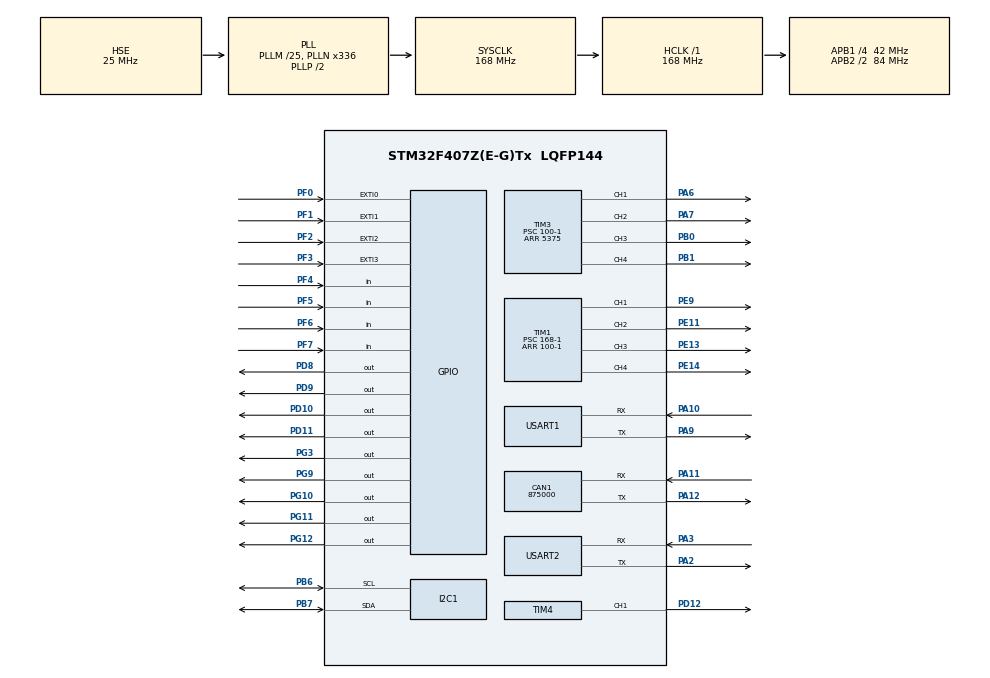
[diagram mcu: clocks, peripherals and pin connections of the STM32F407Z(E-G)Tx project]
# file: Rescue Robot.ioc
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CAN1.BS1=CAN_BS1_1TQ
CAN1.BS2=CAN_BS2_1TQ
CAN1.CalculateBaudRate=875000
CAN1.CalculateTimeBit=1142
CAN1.CalculateTimeQuantum=380.95238095238096
Mcu.Family=STM32F4
Mcu.Name=STM32F407Z(E-G)Tx
Mcu.Package=LQFP144
NVIC.PriorityGroup=NVIC_PRIORITYGROUP_4
PA10.Mode=Asynchronous
PA10.Signal=USART1_RX
PA11.Mode=CAN_Activate
PA11.Signal=CAN1_RX
PA12.Mode=CAN_Activate
PA12.Signal=CAN1_TX
PA13.Mode=Serial_Wire
PA13.Signal=SYS_JTMS-SWDIO
PA14.Mode=Serial_Wire
PA14.Signal=SYS_JTCK-SWCLK
PA2.Mode=Asynchronous
PA2.Signal=USART2_TX
PA3.Mode=Asynchronous
PA3.Signal=USART2_RX
PA6.Signal=S_TIM3_CH1
PA7.Signal=S_TIM3_CH2
PA9.Mode=Asynchronous
PA9.Signal=USART1_TX
PB0.Signal=S_TIM3_CH3
PB1.Signal=S_TIM3_CH4
PB6.Mode=I2C
PB6.Signal=I2C1_SCL
PB7.Mode=I2C
PB7.Signal=I2C1_SDA
PD10.GPIO_Speed=GPIO_SPEED_FREQ_VERY_HIGH
PD10.Signal=GPIO_Output
PD11.GPIO_Speed=GPIO_SPEED_FREQ_VERY_HIGH
PD11.Signal=GPIO_Output
PD12.Signal=S_TIM4_CH1
PD8.GPIO_Speed=GPIO_SPEED_FREQ_VERY_HIGH
PD8.Signal=GPIO_Output
PD9.GPIO_Speed=GPIO_SPEED_FREQ_VERY_HIGH
PD9.Signal=GPIO_Output
PE11.Signal=S_TIM1_CH2
PE13.Signal=S_TIM1_CH3
PE14.Signal=S_TIM1_CH4
PE9.Signal=S_TIM1_CH1
PF0.GPIO_ModeDefaultEXTI=GPIO_MODE_IT_RISING_FALLING
PF0.Signal=GPXTI0
PF1.GPIO_ModeDefaultEXTI=GPIO_MODE_IT_RISING_FALLING
PF1.Signal=GPXTI1
PF2.GPIO_ModeDefaultEXTI=GPIO_MODE_IT_RISING_FALLING
PF2.Signal=GPXTI2
PF3.GPIO_ModeDefaultEXTI=GPIO_MODE_IT_RISING_FALLING
PF3.Signal=GPXTI3
PF4.GPIO_Mode=GPIO_MODE_INPUT
PF4.Signal=GPIO_Input
PF5.GPIO_Mode=GPIO_MODE_INPUT
PF5.Signal=GPIO_Input
PF6.GPIO_Mode=GPIO_MODE_INPUT
PF6.Signal=GPIO_Input
PF7.GPIO_Mode=GPIO_MODE_INPUT
PF7.Signal=GPIO_Input
PG10.GPIO_Speed=GPIO_SPEED_FREQ_VERY_HIGH
PG10.Signal=GPIO_Output
PG11.GPIO_Speed=GPIO_SPEED_FREQ_VERY_HIGH
PG11.Signal=GPIO_Output
PG12.GPIO_Speed=GPIO_SPEED_FREQ_VERY_HIGH
PG12.Signal=GPIO_Output
PG3.GPIO_ModeDefaultOutputPP=GPIO_MODE_OUTPUT_PP
PG3.Signal=GPIO_Output
PG9.GPIO_Speed=GPIO_SPEED_FREQ_VERY_HIGH
PG9.Signal=GPIO_Output
PH0-OSC_IN.Mode=HSE-External-Oscillator
PH0-OSC_IN.Signal=RCC_OSC_IN
PH1-OSC_OUT.Mode=HSE-External-Oscillator
PH1-OSC_OUT.Signal=RCC_OSC_OUT
ProjectManager.HeapSize=0x200
ProjectManager.StackSize=0x400
ProjectManager.TargetToolchain=MDK-ARM V5.32
RCC.48MHZClocksFreq_Value=84000000
RCC.AHBFreq_Value=168000000
RCC.APB1CLKDivider=RCC_HCLK_DIV4
RCC.APB1Freq_Value=42000000
RCC.APB1TimFreq_Value=84000000
RCC.APB2CLKDivider=RCC_HCLK_DIV2
RCC.APB2Freq_Value=84000000
RCC.APB2TimFreq_Value=168000000
RCC.CortexFreq_Value=168000000
RCC.HCLKFreq_Value=168000000
RCC.HSE_VALUE=25000000
RCC.HSI_VALUE=16000000
RCC.LSE_VALUE=32768
RCC.PLLM=25
RCC.PLLN=336
RCC.PLLSourceVirtual=RCC_PLLSOURCE_HSE
RCC.SYSCLKFreq_VALUE=168000000
RCC.SYSCLKSource=RCC_SYSCLKSOURCE_PLLCLK
RCC.VCOOutputFreq_Value=336000000
SH.S_TIM1_CH1.0=TIM1_CH1,PWM Generation1 CH1
SH.S_TIM1_CH2.0=TIM1_CH2,PWM Generation2 CH2
SH.S_TIM1_CH3.0=TIM1_CH3,PWM Generation3 CH3
SH.S_TIM1_CH4.0=TIM1_CH4,PWM Generation4 CH4
SH.S_TIM3_CH1.0=TIM3_CH1,PWM Generation1 CH1
SH.S_TIM3_CH2.0=TIM3_CH2,PWM Generation2 CH2
SH.S_TIM3_CH3.0=TIM3_CH3,PWM Generation3 CH3
SH.S_TIM3_CH4.0=TIM3_CH4,PWM Generation4 CH4
SH.S_TIM4_CH1.0=TIM4_CH1,PWM Generation1 CH1
TIM1.Channel-PWM\ Generation1\ CH1=TIM_CHANNEL_1
TIM1.Channel-PWM\ Generation2\ CH2=TIM_CHANNEL_2
TIM1.Channel-PWM\ Generation3\ CH3=TIM_CHANNEL_3
TIM1.Channel-PWM\ Generation4\ CH4=TIM_CHANNEL_4
TIM1.Period=100-1
TIM1.Prescaler=168-1
TIM3.AutoReloadPreload=TIM_AUTORELOAD_PRELOAD_ENABLE
TIM3.Channel-PWM\ Generation1\ CH1=TIM_CHANNEL_1
TIM3.Channel-PWM\ Generation2\ CH2=TIM_CHANNEL_2
TIM3.Channel-PWM\ Generation3\ CH3=TIM_CHANNEL_3
TIM3.Channel-PWM\ Generation4\ CH4=TIM_CHANNEL_4
TIM3.Period=5375
TIM3.Prescaler=100-1
TIM4.Channel-PWM\ Generation1\ CH1=TIM_CHANNEL_1
TIM4.Period=5375
TIM4.Prescaler=100
USART1.VirtualMode=VM_ASYNC
USART2.VirtualMode=VM_ASYNC
VP_TIM1_VS_ClockSourceINT.Mode=Internal
VP_TIM3_VS_ClockSourceINT.Mode=Internal
VP_TIM4_VS_ClockSourceINT.Mode=Internal
board=custom

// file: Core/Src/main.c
/* USER CODE BEGIN Header */
/**
  ******************************************************************************
  * @file           : main.c
  * @brief          : Main program body
  ******************************************************************************
  * @attention
  *
  * Copyright (c) 2025 STMicroelectronics.
  * All rights reserved.
  *
  * This software is licensed under terms that can be found in the LICENSE file
  * in the root directory of this software component.
  * If no LICENSE file comes with this software, it is provided AS-IS.
  *
  ******************************************************************************
  */
/* USER CODE END Header */
#include "main.h"
#include "can.h"
#include "i2c.h"
#include "tim.h"
#include "usart.h"
#include "gpio.h"

void SystemClock_Config(void);

int main(void)
{

  /* MCU Configuration--------------------------------------------------------*/

  /* Reset of all peripherals, Initializes the Flash interface and the Systick. */
  HAL_Init();

  /* Configure the system clock */
  SystemClock_Config();

  /* Initialize all configured peripherals */
  MX_GPIO_Init();
  MX_CAN1_Init();
  MX_I2C1_Init();
  MX_TIM1_Init();
  MX_TIM3_Init();
  MX_TIM4_Init();
  MX_USART1_UART_Init();
  MX_USART2_UART_Init();
  /* USER CODE BEGIN 2 */
  HAL_TIM_PWM_Start(&htim3, TIM_CHANNEL_1);
  /* USER CODE END 2 */

  /* Infinite loop */
  /* USER CODE BEGIN WHILE */
  while (1)
  {
    // HAL_GPIO_WritePin(GPIOG, GPIO_PIN_9, GPIO_PIN_SET);
    // HAL_GPIO_WritePin(GPIOG, GPIO_PIN_10, GPIO_PIN_RESET);
    __HAL_TIM_SET_COMPARE(&htim3, TIM_CHANNEL_1, 403);
    /* USER CODE END WHILE */

  }
}

void SystemClock_Config(void)
{
  RCC_OscInitTypeDef RCC_OscInitStruct = {0};
  RCC_ClkInitTypeDef RCC_ClkInitStruct = {0};

  /** Configure the main internal regulator output voltage
  */
  __HAL_RCC_PWR_CLK_ENABLE();
  __HAL_PWR_VOLTAGESCALING_CONFIG(PWR_REGULATOR_VOLTAGE_SCALE1);

  /** Initializes the RCC Oscillators according to the specified parameters
  * in the RCC_OscInitTypeDef structure.
  */
  RCC_OscInitStruct.OscillatorType = RCC_OSCILLATORTYPE_HSE;
  RCC_OscInitStruct.HSEState = RCC_HSE_ON;
  RCC_OscInitStruct.PLL.PLLState = RCC_PLL_ON;
  RCC_OscInitStruct.PLL.PLLSource = RCC_PLLSOURCE_HSE;
  RCC_OscInitStruct.PLL.PLLM = 25;
  RCC_OscInitStruct.PLL.PLLN = 336;
  RCC_OscInitStruct.PLL.PLLP = RCC_PLLP_DIV2;
  RCC_OscInitStruct.PLL.PLLQ = 4;
  if (HAL_RCC_OscConfig(&RCC_OscInitStruct) != HAL_OK)
  {
    Error_Handler();
  }

  /** Initializes the CPU, AHB and APB buses clocks
  */
  RCC_ClkInitStruct.ClockType = RCC_CLOCKTYPE_HCLK|RCC_CLOCKTYPE_SYSCLK
                              |RCC_CLOCKTYPE_PCLK1|RCC_CLOCKTYPE_PCLK2;
  RCC_ClkInitStruct.SYSCLKSource = RCC_SYSCLKSOURCE_PLLCLK;
  RCC_ClkInitStruct.AHBCLKDivider = RCC_SYSCLK_DIV1;
  RCC_ClkInitStruct.APB1CLKDivider = RCC_HCLK_DIV4;
  RCC_ClkInitStruct.APB2CLKDivider = RCC_HCLK_DIV2;

  if (HAL_RCC_ClockConfig(&RCC_ClkInitStruct, FLASH_LATENCY_5) != HAL_OK)
  {
    Error_Handler();
  }
}

void Error_Handler(void)
{
  __disable_irq();
  while (1)
  {
  }
}
